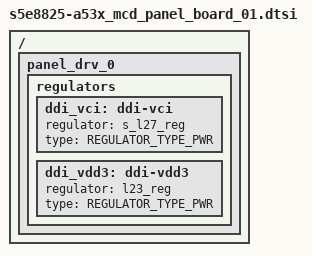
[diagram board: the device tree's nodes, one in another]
/*
 * Samsung Exynos SoC series Panel driver
 *
 * Copyright (c) 2021 Samsung Electronics Co., Ltd
 *
 * This program is free software; you can redistribute it and/or modify
 * it under the terms of the GNU General Public License version 2 as
 * published by the Free Software Foundation.
 */


/ {
	fragment@panel_drv {
		target-path = "/";
		__overlay__ {
			panel_drv_0: panel_drv_0 {
				regulators {
					ddi_vci: ddi-vci {
						regulator = <&s_l27_reg>;
						type = <REGULATOR_TYPE_PWR>;
					};

					ddi_vdd3: ddi-vdd3 {
						regulator = <&l23_reg>;
						type = <REGULATOR_TYPE_PWR>;
					};
				};
			};
		};
	};
};
